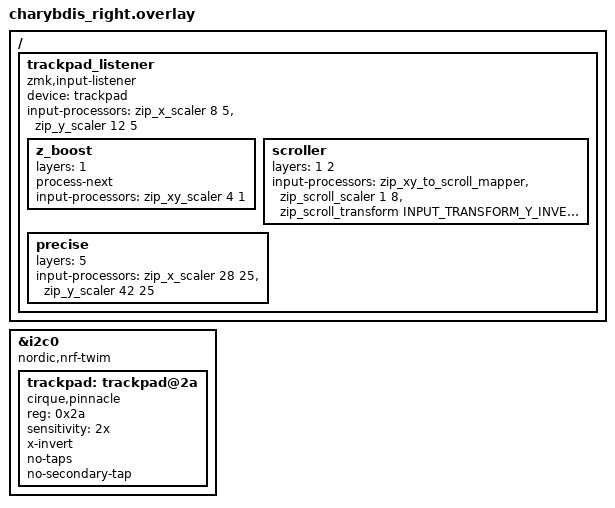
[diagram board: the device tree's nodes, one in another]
#include <input/processors/code_mapper.dtsi>
#include <input/processors/scaler.dtsi>
#include <input/processors/transform.dtsi>
#include <dt-bindings/zmk/input_transform.h>

&i2c0 {
    status = "okay";
    compatible = "nordic,nrf-twim";
    // nice_nano pinctrl: SDA = P0.17, SCL = P0.20

    trackpad: trackpad@2a {
        status = "okay";
        compatible = "cirque,pinnacle";
        reg = <0x2a>;
        // No DR pin wired: the driver polls instead (CONFIG_INPUT_PINNACLE_POLL_INTERVAL_MS)
        sensitivity = "2x";
        // rotate-90;
        x-invert;
        // y-invert;
        // rotation-deg = <180>;
        no-taps;
        no-secondary-tap;
    };
};

/ {
    trackpad_listener {
        compatible = "zmk,input-listener";
        device = <&trackpad>;
        // Vertical axis 1.5x faster than horizontal
        input-processors = <&zip_x_scaler 8 5 &zip_y_scaler 12 5>;

        // Overrides run in order. Holding Z (layer 6) first doubles the raw
        // movement and passes it on, so scroll is 4x faster with Z held and
        // the precise node compensates for the doubling.
        z_boost {
            layers = <1>;
            process-next;
            input-processors = <&zip_xy_scaler 4 1>;
        };

        scroller {
            layers = <1 2>;
            input-processors = <&zip_xy_to_scroll_mapper &zip_scroll_scaler 1 8 &zip_scroll_transform INPUT_TRANSFORM_Y_INVERT>;
        };

        // 30% slower than the base speed on both axes (0.7 x 8/5 and 0.7 x 12/5).
        // This override replaces the base processors, so it scales raw movement.
        precise {
            layers = <5>;
            input-processors = <&zip_x_scaler 28 25 &zip_y_scaler 42 25>;
        };
    };
};
